# EFR32FG23B020F128GM40 register map
Vendor: Silicon Labs; Series: EFR32; File version: B
Registers are 32-bit, read-write, reset 0x0 unless marked. A register's access mark holds for its fields unless they carry their own. Offsets are from the block's base; [hi:lo] are bit positions; {n}, {i} and the like mark numbered series; 'fields as' and 'values as' point back to an identical list.

## MODEM_S (part 2 of 2) — MODEM_S Registers
Base 0xA8014000
Same registers: MODEM_NS 0xB8014000
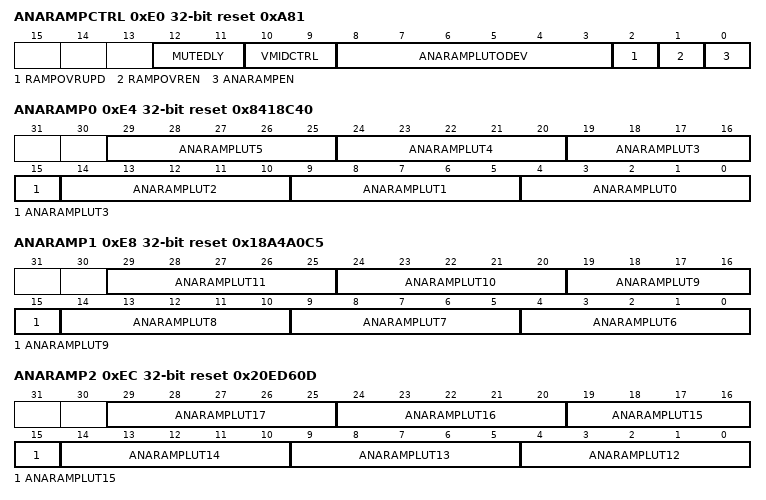
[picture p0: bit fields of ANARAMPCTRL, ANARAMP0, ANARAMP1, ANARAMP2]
0xE0 ANARAMPCTRL reset 0xA81
  [12:11] MUTEDLY — PA Analog Ramp mute delay
    0=TIME0US (Mute to ramp drv/odev delay set to 0us); 1=TIME0P5US (Mute to ramp drv/odev delay set to 0.5us); 2=TIME0P25US (Mute to ramp drv/odev delay set to 0.25us); 3=NOTUSED (Unused Mute to ramp drv/odev delay value)
  [10:9] VMIDCTRL — PA Analog Ramp VMID control
    0=OFF (en_xdrv_vmid always off); 1=MID (en_xdrv_vmid ramp_drv threshold set to midscale); 2=HIGH (en_xdrv_vmid ramp_drv threshold set to highest level); 3=ON (en_xdrv_vmid always on)
  [8:3] ANARAMPLUTODEV — Analog Ramp LUT ODEV switch over
  [2] RAMPOVRUPD wo — PA Analog Ramp Override Update Pulse
  [1] RAMPOVREN — PA Analog Ramp Override
  [0] ANARAMPEN — PA Analog Ramp Enable
0xE4 ANARAMP0 reset 0x8418C40
  [5n+4:5n] ANARAMPLUT{n} (n=0..5) — Analog Ramp LUT
0xE8 ANARAMP1 reset 0x18A4A0C5
  [5n-26:5n-30] ANARAMPLUT{n} (n=6..11) — Analog Ramp LUT
0xEC ANARAMP2 reset 0x20ED60D
  [5n-56:5n-60] ANARAMPLUT{n} (n=12..17) — Analog Ramp LUT
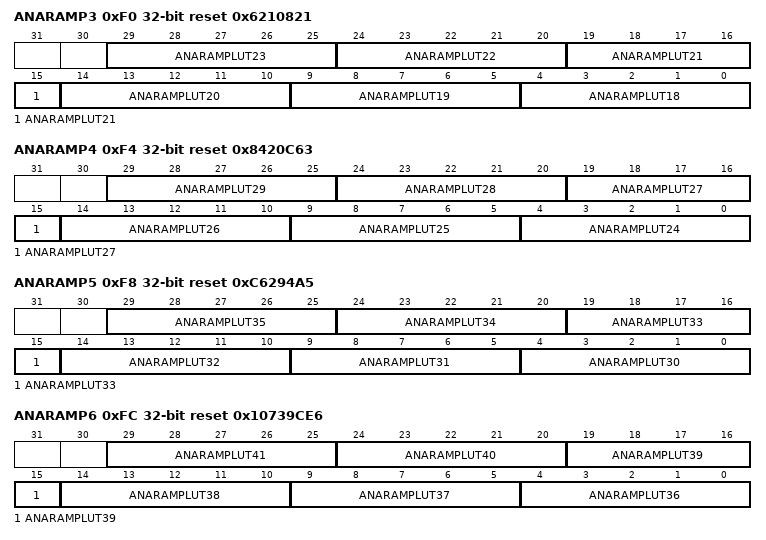
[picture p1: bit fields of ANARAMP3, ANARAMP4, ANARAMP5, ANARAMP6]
0xF0 ANARAMP3 reset 0x6210821
  [5n-86:5n-90] ANARAMPLUT{n} (n=18..23) — Analog Ramp LUT
0xF4 ANARAMP4 reset 0x8420C63
  [5n-116:5n-120] ANARAMPLUT{n} (n=24..29) — Analog Ramp LUT
0xF8 ANARAMP5 reset 0xC6294A5
  [5n-146:5n-150] ANARAMPLUT{n} (n=30..35) — Analog Ramp LUT
0xFC ANARAMP6 reset 0x10739CE6
  [5n-176:5n-180] ANARAMPLUT{n} (n=36..41) — Analog Ramp LUT
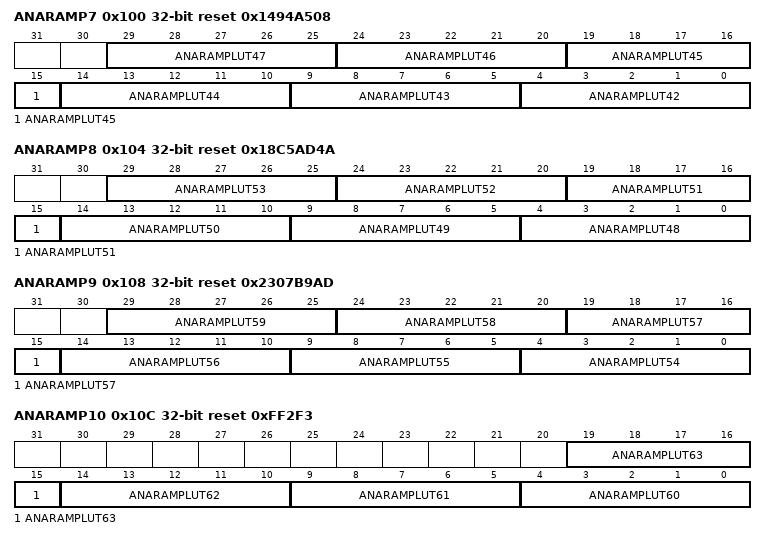
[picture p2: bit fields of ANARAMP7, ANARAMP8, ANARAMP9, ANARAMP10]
0x100 ANARAMP7 reset 0x1494A508
  [5n-206:5n-210] ANARAMPLUT{n} (n=42..47) — Analog Ramp LUT
0x104 ANARAMP8 reset 0x18C5AD4A
  [5n-236:5n-240] ANARAMPLUT{n} (n=48..53) — Analog Ramp LUT
0x108 ANARAMP9 reset 0x2307B9AD
  [5n-266:5n-270] ANARAMPLUT{n} (n=54..59) — Analog Ramp LUT
0x10C ANARAMP10 reset 0xFF2F3
  [5n-296:5n-300] ANARAMPLUT{n} (n=60..63) — Analog Ramp LUT
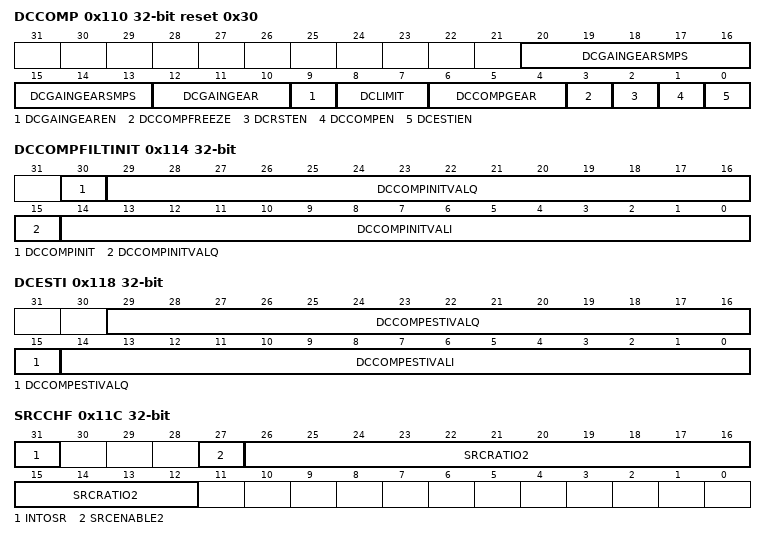
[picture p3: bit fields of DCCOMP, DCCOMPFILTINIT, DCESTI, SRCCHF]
0x110 DCCOMP reset 0x30
  [20:13] DCGAINGEARSMPS — DC Offset Gain Change Samples
  [12:10] DCGAINGEAR — DC Offset Gain Change Filter Gear
  [9] DCGAINGEAREN — DC Offset Gain Change Filter Gear Enable
  [8:7] DCLIMIT — DC offset limit
    0=FULLSCALE (1000 mV); 1=FULLSCALEBY4 (250 mV); 2=FULLSCALEBY8 (125 mV); 3=FULLSCALEBY16 (62 mV)
  [6:4] DCCOMPGEAR — DC Offset Compensation Filter Gear
  [3] DCCOMPFREEZE — DC Offset Compensation Filter Freeze
  [2] DCRSTEN — DC Compensation Filter Reset Enable
  [1] DCCOMPEN — DC Offset Compensation Enable
  [0] DCESTIEN — DC Offset Estimation Enable
0x114 DCCOMPFILTINIT
  [30] DCCOMPINIT — Initialize filter state
  [29:15] DCCOMPINITVALQ — Q-channel initialization value
  [14:0] DCCOMPINITVALI — I-channel initialization value
0x118 DCESTI ro
  [29:15] DCCOMPESTIVALQ — Q-channel DC-Offset Estimated value
  [14:0] DCCOMPESTIVALI — I-channel DC-Offset Estimated value
0x11C SRCCHF
  [31] INTOSR — Forcing Integer OSR
  [27] SRCENABLE2 — SRC2 enable
  [26:12] SRCRATIO2 — SRC2 ratio
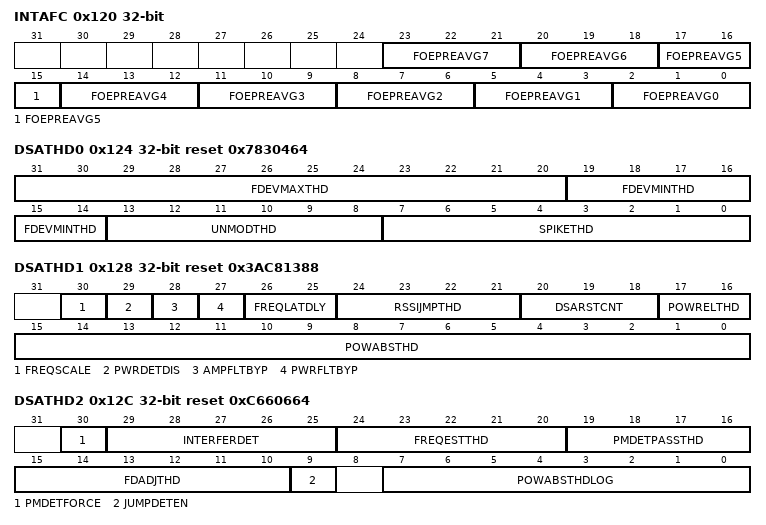
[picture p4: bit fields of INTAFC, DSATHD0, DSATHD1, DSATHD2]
0x120 INTAFC
  [23:21] FOEPREAVG7 — Eighth estimate
  [20:18] FOEPREAVG6 — Seventh estimate
  [17:15] FOEPREAVG5 — Sixth estimate
  [14:12] FOEPREAVG4 — Fifth estimate
  [11:9] FOEPREAVG3 — Fourth estimate
  [8:6] FOEPREAVG2 — Third estimate
  [5:3] FOEPREAVG1 — Second estimate
  [2:0] FOEPREAVG0 — First estimate
0x124 DSATHD0 reset 0x7830464
  [31:20] FDEVMAXTHD — Frequency deviation maximum threshold
  [19:14] FDEVMINTHD — Frequency deviation minimum threshold
  [13:8] UNMODTHD — Unmodulated carrier detector threshold
  [7:0] SPIKETHD — Spike threshold
0x128 DSATHD1 reset 0x3AC81388
  [30] FREQSCALE — Frequency scale factor
  [29] PWRDETDIS — Power detection disabled
  [28] AMPFLTBYP — Amplitude filter bypass
  [27] PWRFLTBYP — Power filter bypass
  [26:25] FREQLATDLY — Frequency late delay
  [24:21] RSSIJMPTHD — RSSI jump detector threshold
  [20:18] DSARSTCNT — DSA reset counter
  [17:16] POWRELTHD — Relative power detector threshold
    0=DISABLED (Threshold is 6dB. The relative power detector will trigger when the current RSSI is 6dB stronger than the previously detected RSSI.); 1=MODE1 (Threshold is 9dB. The relative power detector will trigger when the current RSSI is 9dB stronger than the previously detected RSSI.); 2=MODE2 (Threshold is 12dB. The relative power detector will trigger when the current RSSI is 12dB stronger than the previously detected RSSI.); 3=MODE3 (Threshold is 15dB. The relative power detector will trigger when the current RSSI is 15dB stronger than the previously detected RSSI.)
  [15:0] POWABSTHD — Power absolute threshold
0x12C DSATHD2 reset 0xC660664
  [30] PMDETFORCE — Force DSA preamble detector
  [29:25] INTERFERDET — Interference detection threshold
  [24:20] FREQESTTHD — Frequency Estimation Timeout Threshold
  [19:16] PMDETPASSTHD — DSA Preamble detection counter threshold
  [15:10] FDADJTHD — Frequency deviation ripple threshold
  [9] JUMPDETEN — Power jump detection enable
  [7:0] POWABSTHDLOG — Power threshold in logarithm-scale
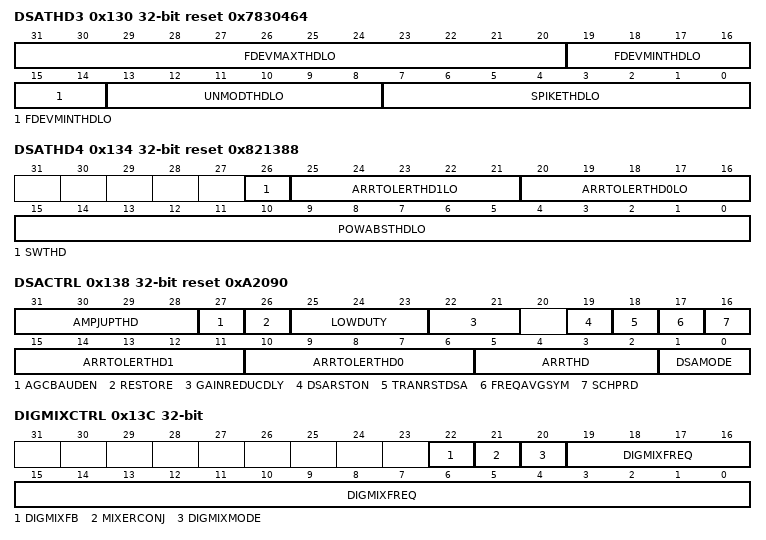
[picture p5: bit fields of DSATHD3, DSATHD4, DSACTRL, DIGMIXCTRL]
0x130 DSATHD3 reset 0x7830464
  [31:20] FDEVMAXTHDLO — Frequency deviation maximum threshold
  [19:14] FDEVMINTHDLO — Frequency deviation minimum threshold
  [13:8] UNMODTHDLO — Unmodulated carrier detector threshold
  [7:0] SPIKETHDLO — Spike threshold
0x134 DSATHD4 reset 0x821388
  [26] SWTHD — Enable switch threshold for low power
  [25:21] ARRTOLERTHD1LO — Arrival tolerance threshold 1
  [20:16] ARRTOLERTHD0LO — Arrival tolerance threshold 0
  [15:0] POWABSTHDLO — Power absolute threshold for low power
0x138 DSACTRL reset 0xA2090
  [31:28] AMPJUPTHD — Amplitude jump detection thrshold
  [27] AGCBAUDEN — Consider Baud_en from AGC
  [26] RESTORE — Power detector reset of DSA
  [25:23] LOWDUTY — Low duty cycle delay
  [22:21] GAINREDUCDLY — Detection Delay of AGC gain reduction
  [19] DSARSTON — DSA detection reset
  [18] TRANRSTDSA — power transient detector Reset DSA
  [17] FREQAVGSYM — DSA frequency estimation averaging
    0=AVG2TS (Frequency estimation over 2 symbol periods.); 1=AVG4TS (Frequency estimation over 4 symbol periods.)
  [16] SCHPRD — Search period window length
    0=TS2 (The search period is 2 symbol periods.); 1=TS4 (The search period is 4 symbol periods.)
  [15:11] ARRTOLERTHD1 — Arrival tolerance threshold 1
  [10:6] ARRTOLERTHD0 — Arrival tolerance threshold 0
  [5:2] ARRTHD — Signal arrival valid counter threshold
  [1:0] DSAMODE — Mode of Digital Signal Arrival detector
    0=DISABLED (DSA is disabled); 1=ENABLED (DSA is enabled by the relative/absolute RSSI detector and is reset by using detectors for spike content and frequency deviation. The RSSI jump detector is used to recover from false detects.)
0x13C DIGMIXCTRL
  [22] DIGMIXFB — Digital mixer Frequency Correction
  [21] MIXERCONJ — Digital mixer input conjugate
  [20] DIGMIXMODE — Digital mixer frequency control
    0=CFOSR (Mixer frequency specified by CFOSR.); 1=DIGMIXFREQ (Mixer frequency specified by DIGMIXFREQ.)
  [19:0] DIGMIXFREQ — Digital mixer frequency control word
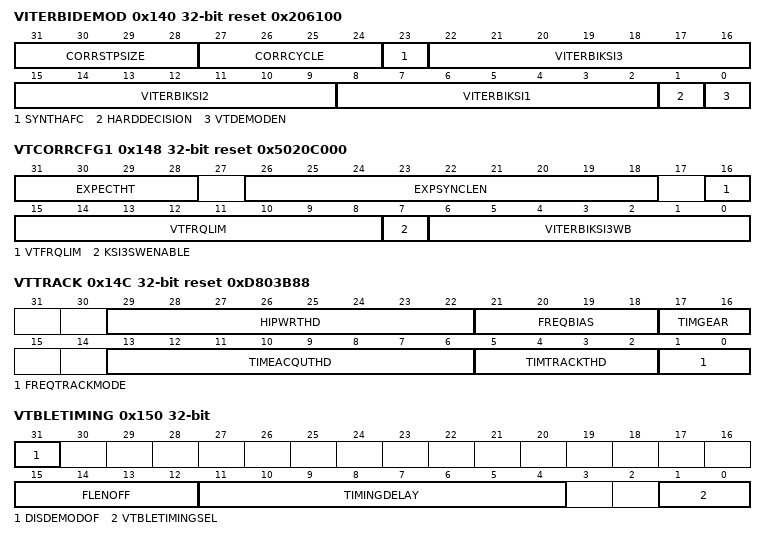
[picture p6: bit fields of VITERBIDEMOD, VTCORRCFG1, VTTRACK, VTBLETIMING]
0x140 VITERBIDEMOD reset 0x206100
  [31:28] CORRSTPSIZE — Correction step size
  [27:24] CORRCYCLE — Correction cycles
  [23] SYNTHAFC — Synthesizer AFC in Viterbi demod
  [22:16] VITERBIKSI3
  [15:9] VITERBIKSI2
  [8:2] VITERBIKSI1
  [1] HARDDECISION
  [0] VTDEMODEN — Viterbi demodulator enable
0x144 VTCORRCFG0 reset 0x123556B7
  [31:0] EXPECTPATT — Expected pattern
0x148 VTCORRCFG1 reset 0x5020C000
  [31:28] EXPECTHT — Expected patterns head and tail
  [26:18] EXPSYNCLEN — Expected sync length
  [16:8] VTFRQLIM — Viterbi frequency limiter
  [7] KSI3SWENABLE — WB KSI3 Switching Enable
  [6:0] VITERBIKSI3WB — WB KSI3
0x14C VTTRACK reset 0xD803B88
  [29:22] HIPWRTHD — High Power detection threshold
  [21:18] FREQBIAS — Frequency estimation bias
  [17:16] TIMGEAR — Timing Gear
    0=GEAR0 (Execute timing tracking regardless of difference between Early/Late and Current correlation values. Referred to as fast gear. Same as GEAR3); 1=GEAR1 (Execute timing tracking only when correlation value of Early/Late is 75% or less of the Current correlation value. Referred to as medium gear.); 2=GEAR2 (Execute timing tracking only when correlation value of Early/Late is 50% or less of the Current correlation value. Referred to as slow gear.)
  [13:6] TIMEACQUTHD — Time acquisition threshold
  [5:2] TIMTRACKTHD — Timing tracking threshold
  [1:0] FREQTRACKMODE — Frequency tracking mode
    0=DISABLED (Frequency tracking disabled. Only a one-time frequency offset compensation applied through DSA.); 1=MODE1 (Frequency tracking enabled with one correction, when needed, every 16 symbol periods.); 2=MODE2 (Frequency tracking enabled with one correction, when needed, every 32 symbol periods.); 3=MODE3 (Frequency tracking enabled with one correction, when needed, every 48 symbol periods.)
0x150 VTBLETIMING
  [31] DISDEMODOF — Disable VT Demod Over Flow Detection
  [15:12] FLENOFF — Timing Stamp Frame Length Offset
  [11:4] TIMINGDELAY — Viterbi BLE Delay timer
  [1:0] VTBLETIMINGSEL — Viterbi BLE timing stamp selection
    0=FRAMEDET_DELAY (Delayed frame detection will be used as Timing stamp. This mode should be selected for legacy demod and Long Range BLE demod.); 1=END_FRAME_PULSE (The end of frame detection from Narrow Viterbi demod will be used as Timing stamp. This signal is a narrow pulse signal and pulse width is one xo clock cycle.); 2=END_FRAME (The end of frame detection from Narrow Viterbi demod will be used as Timing stamp. This signal is a wdie pulse signal); 3=INV_END_FRAME (For testing only.)
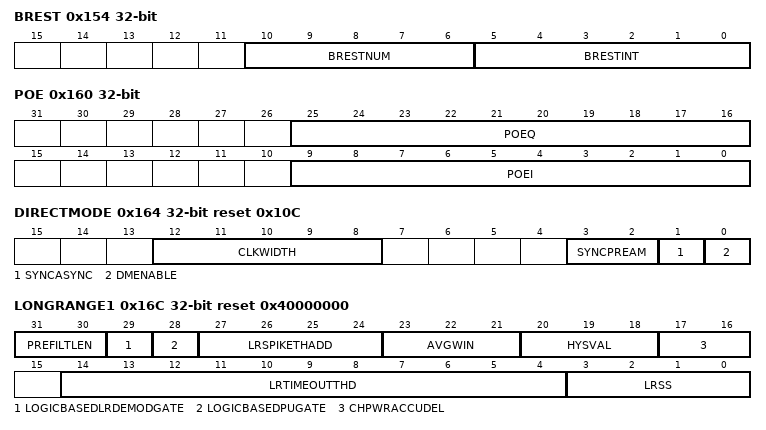
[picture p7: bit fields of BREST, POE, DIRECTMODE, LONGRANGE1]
0x154 BREST ro
  [10:6] BRESTNUM — Fractional part of estimated baudrate
  [5:0] BRESTINT — Integer part of estimated baudrate
0x158 AUTOCG
  [15:0] AUTOCGEN — Enable automatic clock gating
0x15C CGCLKSTOP
  [15:0] FORCEOFF — Manual control clocks
0x160 POE ro
  [25:16] POEQ — Quadrature component of POE.
  [9:0] POEI — In-phase component of POE.
0x164 DIRECTMODE reset 0x10C
  [12:8] CLKWIDTH — Synchronous mode clock pulse width
  [3:2] SYNCPREAM — Synchronous mode preamble
    0=ADD0 (No preamble bits appended); 1=ADD8 (8 preamble bits appended); 2=ADD16 (16 preamble bits appended); 3=ADD32 (32 preamble bits appended)
  [1] SYNCASYNC — Choose Synchronous or Asynchronous mode
  [0] DMENABLE — Enable Direct Mode
0x16C LONGRANGE1 reset 0x40000000
  [31:30] PREFILTLEN — Prefilter Length
    0=LEN32 (Filter length is 32); 1=LEN64 (Filter length is 64); 2=LEN96 (Filter length is 96); 3=LEN128 (Filter length is 128)
  [29] LOGICBASEDLRDEMODGATE — Logic Based Long Range Demod Gating
  [28] LOGICBASEDPUGATE — Logic Based Phase Unwrap Gating
  [27:24] LRSPIKETHADD — Long Range DSA spike threshold addition
  [23:21] AVGWIN — Average window
  [20:18] HYSVAL — Hysteresis Value for BBSS
  [17:16] CHPWRACCUDEL — Channel Power Accumulated Delay
    0=DEL0 (Use accumulated channel power value); 1=DEL32 (Delayed by 32 chips); 2=DEL64 (Delayed by 64 chips)
  [14:4] LRTIMEOUTTHD — Long Range Time Out Threshold
  [3:0] LRSS — Long Range Signal Selection
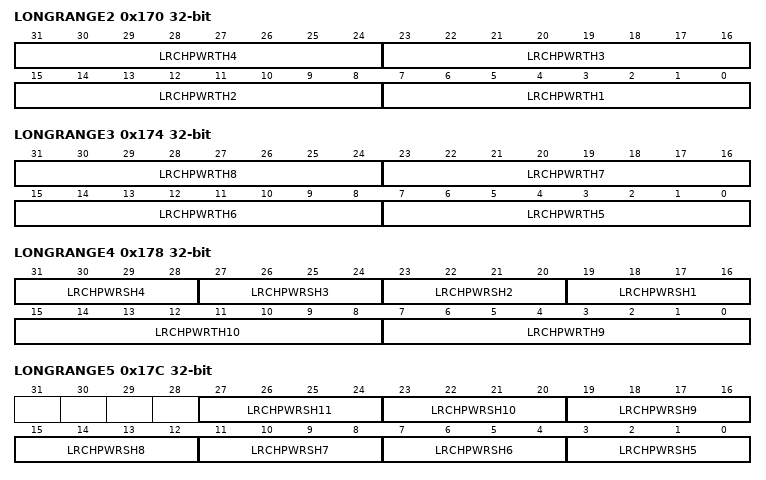
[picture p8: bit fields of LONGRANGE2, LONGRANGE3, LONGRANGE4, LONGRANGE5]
0x170 LONGRANGE2
  [8n-1:8n-8] LRCHPWRTH{n} (n=1..4) — Long Range channel power threshold
0x174 LONGRANGE3
  [8n-33:8n-40] LRCHPWRTH{n} (n=5..8) — Long Range channel power threshold
0x178 LONGRANGE4
  [4n+15:4n+12] LRCHPWRSH{n} (n=1..4) — Long Range channel power shift
  [15:8] LRCHPWRTH10 — Long Range channel power threshold
  [7:0] LRCHPWRTH9 — Long Range channel power threshold
0x17C LONGRANGE5
  [4n-17:4n-20] LRCHPWRSH{n} (n=5..11) — Long Range channel power shift
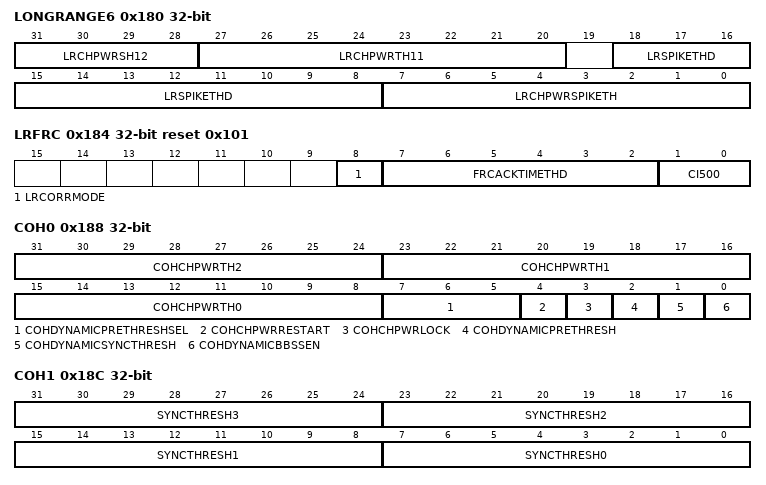
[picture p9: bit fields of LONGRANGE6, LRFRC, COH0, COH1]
0x180 LONGRANGE6
  [31:28] LRCHPWRSH12 — Long Range channel power shift
  [27:20] LRCHPWRTH11 — Long Range channel power threshold
  [18:8] LRSPIKETHD — Long Range spike threshold
  [7:0] LRCHPWRSPIKETH — Long Range channel power spike threshold
0x184 LRFRC reset 0x101
  [8] LRCORRMODE — LR Correlator operation Mode
  [7:2] FRCACKTIMETHD — FRC acknowledge timeout threshold
  [1:0] CI500 — Long Range CI mapping for 500kbps
0x188 COH0
  [31:24] COHCHPWRTH2 — Channel power threshold
  [23:16] COHCHPWRTH1 — Channel power threshold
  [15:8] COHCHPWRTH0 — Channel power threshold
  [7:5] COHDYNAMICPRETHRESHSEL — Dynamic preamble threshold selection
    0=SEL0 (1x sync coeff); 1=SEL1 (0.94x sync coeff); 2=SEL2 (0.88x sync coeff); 3=SEL3 (0.74x sync coeff); 4=SEL4 (0.5x sync coeff)
  [4] COHCHPWRRESTART — Channel power restart
  [3] COHCHPWRLOCK — Channel power lock
    0=TIMDET (Channel power locked when timing is detected); 1=DSADET (Channel power locked when DSA is detected)
  [2] COHDYNAMICPRETHRESH — Dynamic preamble threshold enable bit
  [1] COHDYNAMICSYNCTHRESH — Dynamic syncword threshold enable bit
  [0] COHDYNAMICBBSSEN — Dynamic BBSS enable bit
0x18C COH1
  [8n+7:8n] SYNCTHRESH{n} (n=0..3) — Minimum correlation threshold
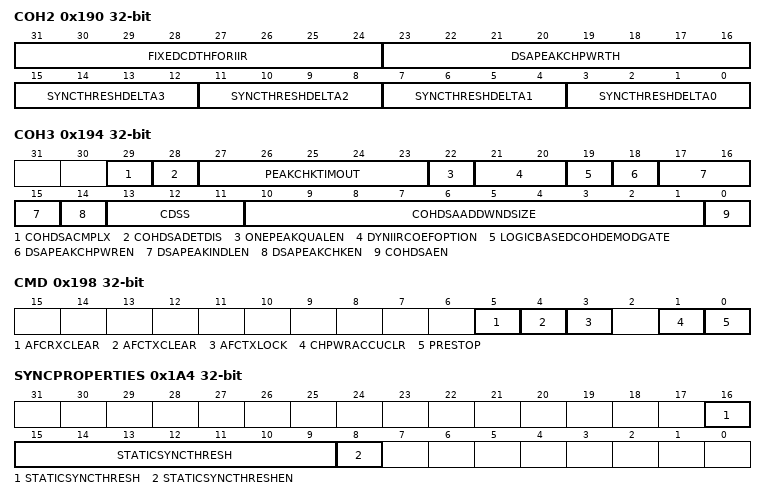
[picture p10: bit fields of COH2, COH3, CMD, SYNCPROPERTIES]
0x190 COH2
  [31:24] FIXEDCDTHFORIIR
  [23:16] DSAPEAKCHPWRTH — DSA Peak Check CHpwr Threshold
  [4n+3:4n] SYNCTHRESHDELTA{n} (n=0..3) — Syncword correlation delta threshold
0x194 COH3
  [29] COHDSACMPLX — DSA Complex
  [28] COHDSADETDIS — DSA Detection Disable
  [27:23] PEAKCHKTIMOUT — Peak Check Time Out
  [22] ONEPEAKQUALEN — One Peak
  [21:20] DYNIIRCOEFOPTION — Dynamic IIR
  [19] LOGICBASEDCOHDEMODGATE — Logic Based clock gate
  [18] DSAPEAKCHPWREN — DSA Peak Check channel power enable
  [17:15] DSAPEAKINDLEN — DSA Peak Index length
  [14] DSAPEAKCHKEN — DSA Peak Checking Enable
  [13:11] CDSS — DSA Signal Selection
  [10:1] COHDSAADDWNDSIZE — DSA additional window size
  [0] COHDSAEN — DSA enable bit
0x198 CMD wo
  [5] AFCRXCLEAR — Clear AFC RX compensation.
  [4] AFCTXCLEAR — Clear AFC TX compensation.
  [3] AFCTXLOCK — Lock AFC TX compensation
  [1] CHPWRACCUCLR — Channel Power Accumulation Clear
  [0] PRESTOP — Preamble stop
0x1A4 SYNCPROPERTIES
  [16:9] STATICSYNCTHRESH — Static Sync Threshold
  [8] STATICSYNCTHRESHEN — Static Sync Threshold Enable
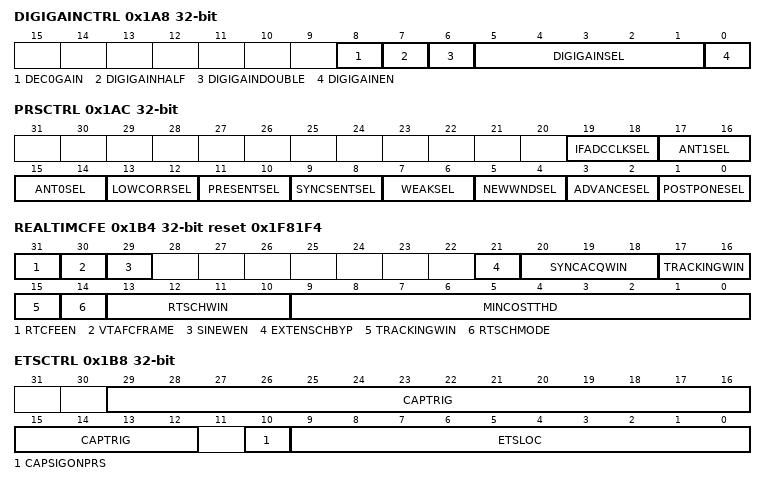
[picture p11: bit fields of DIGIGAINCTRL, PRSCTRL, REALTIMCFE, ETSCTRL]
0x1A8 DIGIGAINCTRL
  [8] DEC0GAIN — DEC0 Gain Select
  [7] DIGIGAINHALF — Digital Gain Halved
  [6] DIGIGAINDOUBLE — Digital Gain Doubled
  [5:1] DIGIGAINSEL — Digital Gain Select
    0=GAINM3; 1=GAINM2P75; 2=GAINM2P5; 3=GAINM2P25; 4=GAINM2; 5=GAINM1P75; 6=GAINM1P5; 7=GAINM1P25; 8=GAINM1; 9=GAINM0P75; 10=GAINM0P5; 11=GAINM0P25; 12=GAINM0; 13=GAINP0P25; 14=GAINP0P5; 15=GAINP0P75; 16=GAINP1; 17=GAINP1P25; 18=GAINP1P5; 19=GAINP1P75; 20=GAINP2; 21=GAINP2P25; 22=GAINP2P5; 23=GAINP2P75; 24=GAINP3
  [0] DIGIGAINEN — Digital Gain Enable
0x1AC PRSCTRL
  [19:18] IFADCCLKSEL, [17:16] ANT1SEL, [15:14] ANT0SEL, [13:12] LOWCORRSEL, [11:10] PRESENTSEL, [9:8] SYNCSENTSEL, [7:6] WEAKSEL, [5:4] NEWWNDSEL, [3:2] ADVANCESEL, [1:0] POSTPONESEL
0x1B4 REALTIMCFE reset 0x1F81F4
  [31] RTCFEEN — TRECS Enable
  [30] VTAFCFRAME — Viterbi AFC FRAME Mode
  [29] SINEWEN — Enable SINE WEIGHT
  [21] EXTENSCHBYP — Bypass extending Search Time
  [20:18] SYNCACQWIN — SYNC Correlator Size
  [17:15] TRACKINGWIN — Correlator size for Tracking
  [14] RTSCHMODE — Real Time CFE searching mode
  [13:10] RTSCHWIN — Real time CFE searching window
  [9:0] MINCOSTTHD — Minimum Cost Threshold
0x1B8 ETSCTRL
  [29:12] CAPTRIG — Trigger to capture
  [10] CAPSIGONPRS — Capture Signal On PRS
  [9:0] ETSLOC — Early Time Stamp Location
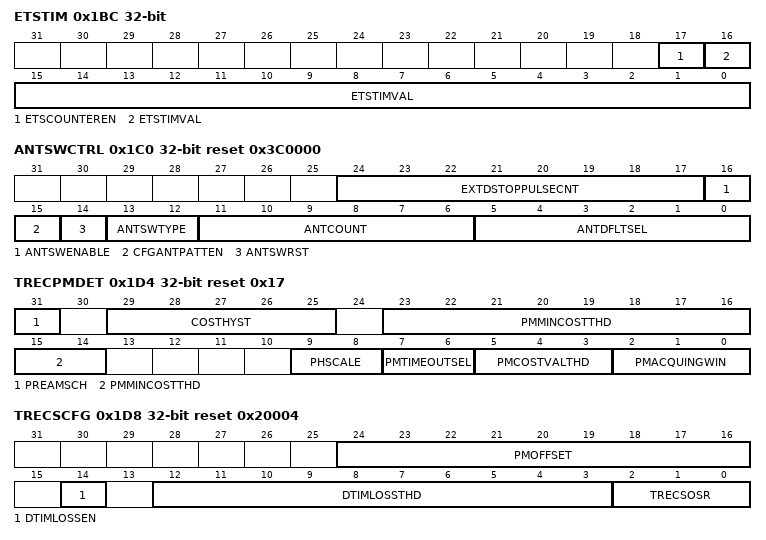
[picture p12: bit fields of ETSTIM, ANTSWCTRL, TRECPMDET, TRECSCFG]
0x1BC ETSTIM
  [17] ETSCOUNTEREN, [16:0] ETSTIMVAL
0x1C0 ANTSWCTRL reset 0x3C0000
  [24:17] EXTDSTOPPULSECNT — Extend Stop Pulse Counter
  [16] ANTSWENABLE
  [15] CFGANTPATTEN — Configure Ant Pattern Enable
  [14] ANTSWRST wo — Ant SW rst pulse
  [13:12] ANTSWTYPE — Ant Switch Type
    0=US_2 (2us ant switching); 1=US_4 (4us ant switching); 2=US_6 (6us ant switching); 3=US_8 (8us ant switching)
  [11:6] ANTCOUNT — Total Ant count
  [5:0] ANTDFLTSEL — Ant Default Select
0x1C4 ANTSWCTRL1 reset 0x6AAAA
  [23:0] TIMEPERIOD — Time Period of xtal
0x1C8 ANTSWSTART
  [17:0] ANTSWSTARTTIM — Ant switch start time
0x1CC ANTSWEND
  [17:0] ANTSWENDTIM — Ant switch start time
0x1D0 TRECPMPATT reset 0x55555555
  [31:0] PMEXPECTPATT — Expected PM pattern
0x1D4 TRECPMDET reset 0x17
  [31] PREAMSCH — PM detection enable in TRECS
  [29:25] COSTHYST — PM Seaching COST HYST
  [23:14] PMMINCOSTTHD — Min. Cost thrshold for TRECS PM
  [9:8] PHSCALE — PHASE Scaler
  [7:6] PMTIMEOUTSEL — PM searching timeout Threshold
  [5:3] PMCOSTVALTHD — Min COST Validation for AFC
  [2:0] PMACQUINGWIN — PM Correlator Size
0x1D8 TRECSCFG reset 0x20004
  [24:16] PMOFFSET — PM SCH ADRESS offsrt
  [14] DTIMLOSSEN — ENABLE TIMING LOSS DETECTION
  [12:3] DTIMLOSSTHD — Timing Loss Threshold
  [2:0] TRECSOSR
0x1DC CFGANTPATT
  [29:0] CFGANTPATTVAL
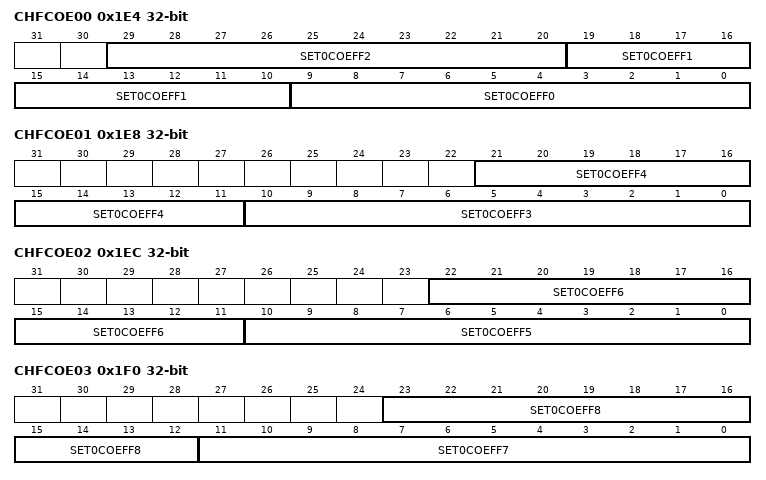
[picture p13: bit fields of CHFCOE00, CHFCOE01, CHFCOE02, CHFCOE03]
0x1E4 CHFCOE00
  [29:20] SET0COEFF2 — SET 0 CHF COE2
  [19:10] SET0COEFF1 — SET 0 CHF COE1
  [9:0] SET0COEFF0 — SET 0 CHF COE0
0x1E8 CHFCOE01
  [21:11] SET0COEFF4 — SET 0 CHF COE4
  [10:0] SET0COEFF3 — SET 0 CHF COE3
0x1EC CHFCOE02
  [22:11] SET0COEFF6 — SET 0 CHF COE6
  [10:0] SET0COEFF5 — SET 0 CHF COE5
0x1F0 CHFCOE03
  [23:12] SET0COEFF8 — SET 0 CHF COE8
  [11:0] SET0COEFF7 — SET 0 CHF COE7
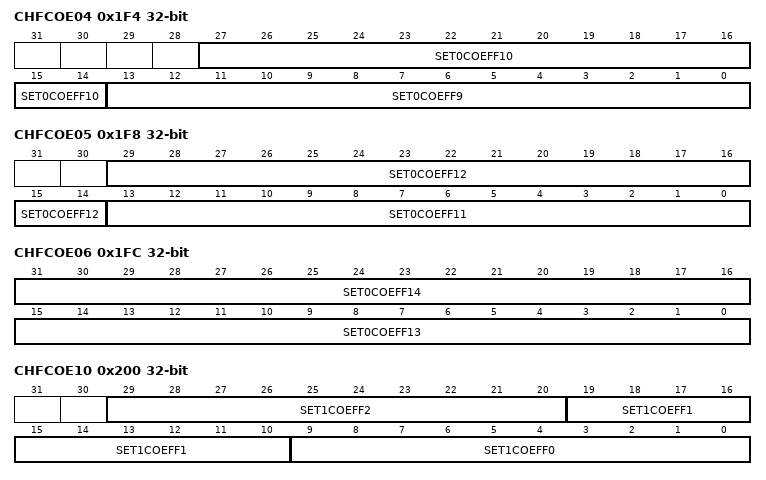
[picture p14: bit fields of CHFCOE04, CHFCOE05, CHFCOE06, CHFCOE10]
0x1F4 CHFCOE04
  [27:14] SET0COEFF10 — SET 0 CHF COE10
  [13:0] SET0COEFF9 — SET 0 CHF COE9
0x1F8 CHFCOE05
  [29:14] SET0COEFF12 — SET 0 CHF COE12
  [13:0] SET0COEFF11 — SET 0 CHF COE11
0x1FC CHFCOE06
  [31:16] SET0COEFF14 — SET 0 CHF COE14
  [15:0] SET0COEFF13 — SET 0 CHF COE13
0x200 CHFCOE10
  [29:20] SET1COEFF2 — SET 1 CHF COE2
  [19:10] SET1COEFF1 — SET 1 CHF COE1
  [9:0] SET1COEFF0 — SET 1 CHF COE0
0x204 CHFCOE11
  [21:11] SET1COEFF4 — SET 1 CHF COE4
  [10:0] SET1COEFF3 — SET 1 CHF COE3
0x208 CHFCOE12
  [22:11] SET1COEFF6 — SET 1 CHF COE6
  [10:0] SET1COEFF5 — SET 1 CHF COE5
0x20C CHFCOE13
  [23:12] SET1COEFF8 — SET 1 CHF COE8
  [11:0] SET1COEFF7 — SET 1 CHF COE7
0x210 CHFCOE14
  [27:14] SET1COEFF10 — SET 1 CHF COE10
  [13:0] SET1COEFF9 — SET 1 CHF COE9
0x214 CHFCOE15
  [29:14] SET1COEFF12 — SET 1 CHF COE12
  [13:0] SET1COEFF11 — SET 1 CHF COE11
0x218 CHFCOE16
  [31:16] SET1COEFF14 — SET 1 CHF COE14
  [15:0] SET1COEFF13 — SET 1 CHF COE13
0x21C CHFCTRL
  [31] SWCOEFFEN — Switch CHF COE. Enable
  [1] FWSELCOEFF — FW Select CHF COE. set
  [0] FWSWCOEFFEN — FW Switch CHF COE. Enable
0x220 CHFLATENCYCTRL
  [1:0] CHFLATENCY
0x224 FRMSCHTIME reset 0x40
  [31] PMENDSCHEN — EnABLE SCH PM END
  [30] DSARSTSYCNEN — ENABLE CLEAN SYNC
  [29] PMRSTSYCNEN — ENABLE CLEAN SYNC
  [15:0] FRMSCHTIME — FRAME SCH TIME OUT THRD
0x228 PREFILTCOEFF reset 0x3B3B3B3B
  [31:0] PREFILTCOEFF — Preamble Filter Coefficients
0x22C RXRESTART reset 0x1860
  [31] FLTRSTEN — RX Chain Filter reset enable
  [30] ANTSWRSTFLTTDIS — ANT SW RESET Filter Disable
  [16] RXRESTARTB4PREDET — whether to restart RX before pre det
  [12] RXRESTARTMATAP — Number of taps for the MA filter
    0=TAPS4; 1=TAPS8
  [11:10] RXRESTARTMACOMPENSEL — Enable the comparator
    0=PRE_DET (preamble detection); 1=FRAME_SYNC_DET (frame/sync detection); 2=BOTH1 (both preamble and frame/sync detection); 3=BOTH2 (both preamble and frame/sync detection)
  [9:8] RXRESTARTMALATCHSEL — latch the RSSI MA filter output
    0=RE_PRE_DET (rising edge of per det); 1=RE_SYNC_DET (rising edge of sync det); 2=EITHER1 (either of the two); 3=EITHER2 (either of the two)
  [7:4] RXRESTARTMATHRESHOLD — Threshold for the RSSI MA filter
    {v}=DB{v} ({v} DB) (v=0..4); 5=DB5; 6=DB6 (6 DB); {v}=DB{v} (v=7..14); 15=DB15 (15 DB)
  [0] RXRESTARTUPONMARSSI — Restart RX upon RSSI MA above threshold
0x230 SQ
  [31:16] SQTIMOUT — SQ Timeout
  [1] SQSWRST wo — SQ hold demod
  [0] SQEN — SQ enable
0x234 SQEXT
  [31:16] SQSTG3TIMOUT — SQ Timeout
  [15:0] SQSTG2TIMOUT — SQ Timeout
0x238 SQI
  [23:16] CHIPERROR ro — Chip errors
  [0] SQISELECT — SQI selection bit
    0=CORR; 1=ERROR
0x23C ANTDIVCTRL
  [10] ANTDIVSELCCA — Antenna switch selection for CSMA
  [9] ANTDIVDISCCA — Antenna switch disable for CSMA
  [8] ENADPRETHRESH — Enable Preamble threshold
    0=DISABLE (Disable use of Preamble threshold after timing detection); 1=ENABLE (Enable use of Preamble threshold after timing detection)
  [7:0] ADPRETHRESH — Preamble threshold
0x240 ANTDIVFW
  [31] FWANTDIVEN — Enable FW ANT-DIV mode
  [1] FWANTSWCMD wo — FW Antenna SW cmd
  [0] FWSELANT — FW antenna selection
0x244 PHDMODANTDIV reset 0xF
  [30] SKIP2ANT — SKIP 2th ANTENNA Evaluate
  [23:16] SKIPCORRTHD — CORR THD to SKIP 2th ANTENNA Evaluate
  [12:5] SKIPRSSITHD — RSSI THD to SKIP 2th ANTENNA Evaluate
  [4:0] ANTWAIT — ANTENNA WAIT TIME
0x248 PHANTDECSION
  [n+28] RSSICORR{n} (n=0..3) — RSSI-CORR Selection in Region{n}
  [18:10] RSSIANDDIVTHD — RSSI Selection in region
  [9:0] CORRANDDIVTHD — Correlation Selection in region
0x24C PHDMODCTRL reset 0x1DF0004
  [31] BCRLEGACYCONC — BCR/TRECS CONCURRENT MODE
  [30] BCRTRECSCONC — BCR/LEGACY CONCURRENT MODE
  [29] BCRDETECTOR — Enbale BCRDMOD Dtetector ONLY
  [28] REMODEN — REMOD ENABLE
  [27:26] REMODOUTSEL — REMOD OUTPUT Selection
  [25:22] REMODDWN — REMOD downsampling ratio
  [21:16] REMODOSR — REMOD INPUT OSR
  [15] PMDETEN — PREAMBLE DET
  [14] RSSIFLTBYP — Bypass RSSI Filering
  [13] PMTIMLOSEN — Preamble timing loss detection
  [12:5] PMTIMLOSTHD — Preamble Timing loss thrshold
  [4:0] PMDETTHD — Preamble Detection Thrshould
0x270 IRCAL
  [15] IRCALIFADCDBG
  [14] IRCALCOEFRSTCMD wo — IRCAL coef reset cmd
  [13] IRCORREN — IR Correction enable bit
  [12:7] MUISHF — MUI shift value
  [5:1] MURSHF — MUR shift value
  [0] IRCALEN — IRCAL enable bit
0x274 IRCALCOEF ro
  [30:16] CIV — CIV coefficient
  [14:0] CRV — CRV coefficient
0x278 IRCALCOEFWR0
  [31] CIVWEN — CIV Coefficient Write Enable
  [30:16] CIVWD — CIV coefficient
  [15] CRVWEN — CIV Coefficient Write Enable
  [14:0] CRVWD — CRV coefficient
0x27C IRCALCOEFWR1
  fields as IRCALCOEFWR0
0x280 ADCTRL1
  [31:0] ADCTRL1 — AD control
0x284 ADCTRL2
  [31:0] ADCTRL2 — AD control
0x288 ADQUAL0 ro
  [25:16] ADRSSI1 — ANT1 RSSI
  [9:0] ADRSSI0 — ANT0 RSSI
0x28C ADQUAL1 ro
  [31:17] ADSTAT1
  [16:0] ADCORR0 — ANT0 CORR
0x290 ADQUAL2 ro
  [25:16] ADRSSI1P — Previous ANT1 RSSI
  [9:0] ADRSSI0P — Previous ANT0 RSSI
0x294 ADQUAL3 ro
  [31:17] ADSTAT2
  [16:0] ADCORR0P — Previous ANT0 CORR
0x298 ADQUAL4 reset 0x200003F
  [31:30] ADGRMODE — Gain reduced mode
  [25:16] ADRSSIGRTHR — RSSI gain reduced threshold
  [5:0] ADAGCGRTHR — AGC gain reduced threshold
0x29C ADQUAL5 reset 0xFFFF
  [16:0] ADDIRECTCORR — AD direct selection correlation
0x2A0 ADQUAL6 reset 0xFFFF
  [31:17] ADBACORRDIFF — AD best antenna correlation diff
  [16:0] ADBACORRTHR — AD best antenna correlation thr
0x2A4 ADQUAL7 reset 0x3FF
  [25:16] ADBARSSIDIFF — AD best antenna RSSI diff
  [9:0] ADBARSSITHR — AD best antenna RSSI thr
0x2A8 ADQUAL8
  [9:8] ADBAMODE — AD best antenna mode
  [5:0] ADBAAGCTHR — AD best antenna AGC thr
0x2AC ADQUAL9 ro
  [16:0] ADCORR1 — ANT1 CORR
0x2B0 ADQUAL10 ro
  [16:0] ADCORR1P — Previous ANT1 CORR
0x2B4 ADFSM0
  [30:27] ADSTAT2SEL
  [26:23] ADSTAT1SEL
  [22] ADSTATREAD
  [21] ADBA ro — best_antenna
  [20] ADAS ro — antsel
  [19] ADTD1P ro — timdet1p
  [18] ADTD1 ro — timdet1
  [17] ADTD0P ro — timdet0p
  [16] ADTD0 ro — timdet0
  [15:12] ADSTATEN ro — Next AD state
  [11:8] ADSTATEP2 ro — 2nd previous AD state
  [7:4] ADSTATEP ro — Previous AD state
  [3:0] ADSTATEC ro — Current AD state
0x2B8 ADFSM1
  [31:16] ADOSETANT1 — AD output mux
  [15:0] ADOSETANT0 — AD output mux
0x2BC ADFSM2
  [31:16] ADORESTARTRX — AD output mux
  [15:0] ADOSWITCHANT — AD output mux
0x2C0 ADFSM3
  [31:16] ADOQUAL1UPDATE — AD output mux
  [15:0] ADOQUAL0UPDATE — AD output mux
0x2C4 ADFSM4
  [31:16] ADOQUAL1CLEAR — AD output mux
  [15:0] ADOQUAL0CLEAR — AD output mux
0x2C8 ADFSM5
  [31:0] ADOMUX — AD output mux
{0x2B4+4i} ADFSM{i} (i=6..13)
  [31:16] ADNEXTSTATESW{2i-11} — AD next states
  [15:0] ADNEXTSTATESW{2i-12} — AD next states
0x2EC ADFSM14
  [31:16] ADFSMCOND1ENA — AD next states
  [15:0] ADFSMCOND0ENA — AD next states
0x2F0 ADFSM15
  [31:16] ADFSMCOND3ENA — AD next states
  [15:0] ADFSMCOND2ENA — AD next states
0x2F4 ADFSM16
  [31:16] ADFSMCOND1ENB — AD next states
  [15:0] ADFSMCOND0ENB — AD next states
0x2F8 ADFSM17
  [31:16] ADFSMCOND3ENB — AD next states
  [15:0] ADFSMCOND2ENB — AD next states
0x2FC ADFSM18
  [31:0] ADFSMCONDSEL — AD next states
0x300 ADFSM19
  [31:16] ADFSMCONDTRUE — AD next states
  [15:0] ADFSMNEXTFORCE — AD next states
0x304 ADFSM20
  [31:16] ADITLEAVEEN — AD FSM IT leave enable
  [15:0] ADITENTEREN — AD FSM IT enter enable
0x308 ADFSM21
  [16] ADUNFREEZE wo — AD FSM unfreeze
  [6:3] ADUNFREEZENEXT — AD FSM unfreeze next state
  [2] ADFROZEN ro — AD FSM frozen
  [1] ADLEAVEFREEZEEN — AD FSM leave freeze enable
  [0] ADENTERFREEZEEN — AD FSM enter freeze enable
0x30C ADFSM22 ro
  [31:16] ADITLEAVESTATUS — AD FSM IT leave status
  [15:0] ADITENTERSTATUS — AD FSM IT enter status
0x310 ADFSM23
  [31:16] ADFSMCOND1ENC — AD next states
  [15:0] ADFSMCOND0ENC — AD next states
0x314 ADFSM24
  [31:16] ADFSMCOND3ENC — AD next states
  [15:0] ADFSMCOND2ENC — AD next states
0x318 ADFSM25
  [31:16] ADFSMCONDOR1 — AD FSM OR cond
  [15:0] ADFSMCONDOR0 — AD FSM OR cond
0x31C ADFSM26
  [31:16] ADFSMCOND1END — AD next states
  [15:0] ADFSMCOND0END — AD next states
0x320 ADFSM27
  [31:16] ADFSMCOND3END — AD next states
  [15:0] ADFSMCOND2END — AD next states
0x324 ADFSM28
  [31:16] ADORESTARTRXFORCE — AD next states
  [15:0] ADOSETANTFORCE — AD next states
0x328 ADFSM29
  [31:16] ADOQUALCLEARFORCE — AD next states
  [15:0] ADOQUALUPDATEFORCE — AD next states
0x32C ADFSM30
  [31:0] ADODEMODRXREQ — AD next states
0x330 BCRCTRL0 reset 0x8857628
  [31:29] CRFAST, [28:26] CRSLOW, [25] DISTOGG, [24] BCRALIGN, [23] BCRFBBYP, [22] BCRERRRSTEN, [21:0] BCRNCOFF
0x334 BCRCTRL1 reset 0x5E07FF
  [31] SLICEFBBYP — SLICE BYP
  [30] PHCOMP2FSK
  [29] BCRSWSYCW
  [28] ESTOSREN
  [27:16] BCROSR
  [15] DISMIDPT
  [14] ESCMIDPT
  [13] RXCOMPLAT
  [12] RXNCOCOMP
  [11] CGAINX2
  [10:0] CRGAIN
0x338 BCRDEMODCTRL reset 0x6890100
  [31] PHSRCSEL
  [30] INVRXBIT
  [29] MANCHPH — Manchester decoder phase
  [28] BBPMDETEN — BINARY BIT PREAMBLE DET
  [27:25] DETECTORSEL
  [24] DIRECTMODE
  [23] SLICERFAST
  [22] NONSTDPK
  [21:20] PMPATTERN
  [19] SKIPSYN
  [18:14] PREATH
  [12] DATAFLTBY — DATA filter Bypass
  [11] CICDINSCALE — CIC INPUT SCALE
  [10] MANCHDLY — Manchester decoder delay
  [9:8] RAWFLTSEL
  [7] SPIKEREMOV
  [6] RAWFASTMA
  [5] LOCKUPBYP
  [4] PH0SIZE
  [3] CONSCHKBYP
  [2] RAWSYN
  [1] PULCORRBYP — BYPASS PULSE CORR
  [0] BCRDEMODEN — BCR DEMOD ENABLE
0x33C BCRDEMODOOK reset 0xA00C03
  [31] BCRDEMODOOK — BCR Demod OOK enable
  [30:28] RAWNDEC — RAW DATA DEC
  [27:25] SQUELCH
  [24:22] ATTACK
  [21:18] DECAY
  [17:16] DECAYSWAL
  [15:13] ABPK — ABOVE PEAK
  [12:8] BWPK
  [7] SQUELCLKEN — Squelch bit clock enable
  [6] MAFREQDWN
  [5] PKTRUNK — PKD TRUNKATION DISABLE
  [3] NOISEFLEST — Noise Floore Estimation Enable
  [2:1] RAWGAIN
  [0] OOKFRZEN
0x340 BCRDEMODAFC0 reset 0x40000000
  [31] ENAFCCLKSW
  [30] EN2TBEST
  [29] AFCGAINOVRFLW
  [15] LARGEFREQERR
  [6:0] ZEROOFF — ZERO OFFSET
0x344 BCRDEMODAFC1 reset 0x10100012
  [31] ENFBPLL
  [30] ENAFC
  [29] HALFPHCOMP
  [28] ENAFCFRZ
  [27] PMRSTEN — PM RST Enable
  [26] SKIPPMDET
  [25] ONESHOTAFCEN
  [24:21] ONESHOTWAITCNT
  [20] NONFRZEN
  [19] ENFZPMEND
  [18] AFCMAEN
  [15:14] GEARSW
  [7:4] SHWAIT
  [3:0] LGWAIT
0x348 BCRDEMOD4FSK0 reset 0xB4299A
  [31] EN4GFSK — Enable BCR demod 4GFSK
  [30] PHCOMPBYP
  [23:16] CODE4GFSK
  [15:0] THD4GFSK
0x34C BCRDEMOD4FSK1 reset 0xB1C
  [31:30] S2PMAP
    0=S2p_mapping0 ({a1,a0}, {a3,a2}, {a5,a4}); 1=S2p_mapping1 ({a0,a1}, {a2,a3}, {a4,a5}); 2=S2p_mapping2 ({a0,a_1},{a2,a1}, {a4,a3}); 3=S2p_mapping3 ({a_1,,a0}, {a1,a2},{a3,a4})
  [23] FDEVCOMPEN — Freq. Dev. Comp. Enable
  [22:16] FDEVCOMPRATIO — Freq. Dev. Comp. Ratio
  [14:8] PHCOMP4FSK1
  [6:0] PHCOMP4FSK0
0x350 BCRDEMODANT reset 0x10020000 — Recommended not to be used.
  [31] BCRDEMODANTDIV
  [28:25] ANT2PMTHD
  [24] BYP1P5
  [23] SKIP2PH
  [22] AGCGAINUPB — AGC GAIN UP
  [21:16] ANWAIT
  [15] SKIP2PHTHD
  [12] BECOEN — BECO MODE Enable
  [10:5] SWANTTIMER
0x354 BCRDEMODRSSI reset 0x60000020
  [31:25] PRWOFFSET — Power measurement Offset
  [12:10] MUTERSSICNT
  [8] RSSIMATAP
  [7:0] RSSIARRTHD
0x358 BCRDEMODARR0 reset 0x600026
  [31] ARRDETEN
  [30] ARRQPM — ARRIVAL QUALIFY PM DET
  [29:28] ARRDETSRC
  [27] EYEXESTFAST
  [26] EYEXESTEN
  [25] SCHFRZEN
  [24:21] ARRDETTHD
  [20:14] PHSPIKETHD — PHASE SPIKE
  [13] DIFF0RSTEN
  [12:8] ARRTOLER
  [7] ARRRSTEN
  [6:4] SCHPRDHI
  [3] EYEQUALEN
  [2:0] SCHPRDLO
0x35C BCRDEMODARR1 reset 0x80000000
  [31] ENCFEQUAL — Enable BCE CFE Qualifer
  [30] KSICOMPEN — BCR KSI COMP. ENABLE
  [29:27] CFEQUALTHD — BCR Demod CFE Qualifer THRD
  [26] BCRCFESRC — BCR CFE INPUT SOURCE
  [25:23] SYMBWMIN — Expected MIN Duration
  [22:18] SYMBWMAX — Expected MAX Duration
  [17:7] EYEOPENTHD — Expected Deviation
  [6:0] ARREYEQUAL
0x360 BCRDEMODARR2
  [31] OUTRNGCHK — OUT RANGE CHECK
  [5] RAWDCHKALWAYON — RAW DATA Quality Check Always on
  [4:0] CONSYMOL — Max.NO. of CONSECTIVE
0x364 BCRDEMODKSI reset 0x2C2020
  [22:16] BCRKSI3, [14:8] BCRKSI2, [6:0] BCRKSI1
0x368 BCRDEMODPMEXP reset 0x58965555
  [31:30] BCRPMACQWIN — BCR PM CORR SIZE
  [29:27] BCRCFESCHWIN — BCR CFEDSA WIN
  [26:25] BCRPHSCALE — SCALING FACTOR
  [23:16] BCRCFECOSTTHD — BCR MinCOST THD
  [15:0] BCRPMEXP — BCR PM Pattern
0x400 SPARE
  [7:0] SPARE
